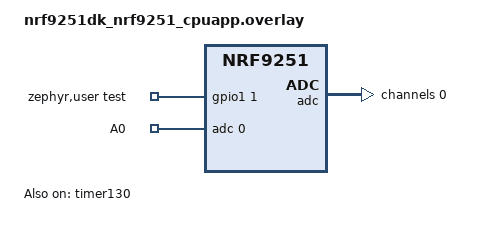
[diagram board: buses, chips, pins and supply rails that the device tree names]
/*
 * Copyright (c) 2026 Nordic Semiconductor ASA
 *
 * SPDX-License-Identifier: LicenseRef-Nordic-5-Clause
 */

/*
 * Required loopbacks:
 * P1.00 (AIN0) <-> P1.01
 */

/ {
	aliases {
		tst-timer = &timer130;
	};

	zephyr,user {
		test-gpios = <&gpio1 1 GPIO_ACTIVE_HIGH>;
		io-channels = <&adc 0>;
		io-channel-names = "A0";
	};
};

dut_adc: &adc {
	#address-cells = <1>;
	#size-cells = <0>;
	memory-regions = <&cpuapp_dma_region>;
	status = "okay";

	channel@0 {
		reg = <0>;
		zephyr,gain = "ADC_GAIN_1";
		zephyr,reference = "ADC_REF_INTERNAL";
		zephyr,acquisition-time = <ADC_ACQ_TIME_DEFAULT>;
		zephyr,input-positive = <NRF_SAADC_AIN0>;
	};
};

&gpio1 {
	status = "okay";
};

&timer130 {
	status = "okay";
};
